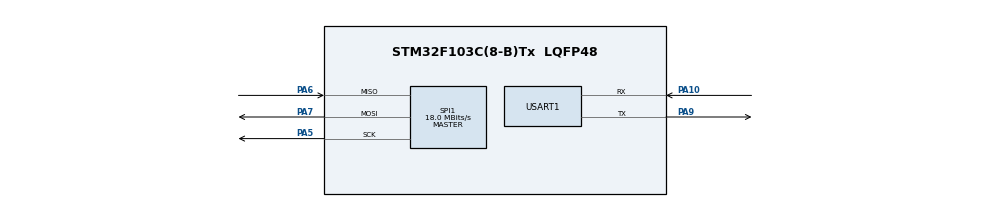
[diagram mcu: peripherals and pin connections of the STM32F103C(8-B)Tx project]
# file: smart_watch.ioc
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Mcu.Family=STM32F1
Mcu.Name=STM32F103C(8-B)Tx
Mcu.Package=LQFP48
NVIC.PriorityGroup=NVIC_PRIORITYGROUP_4
NVIC.SPI1_IRQn=true\:0\:0\:false\:false\:true\:true\:true\:true
NVIC.TIM3_IRQn=true\:15\:0\:false\:false\:true\:false\:true\:true
NVIC.TimeBase=TIM3_IRQn
NVIC.TimeBaseIP=TIM3
PA10.Mode=Asynchronous
PA10.Signal=USART1_RX
PA13.Mode=Serial_Wire
PA13.Signal=SYS_JTMS-SWDIO
PA14.Mode=Serial_Wire
PA14.Signal=SYS_JTCK-SWCLK
PA5.Mode=Full_Duplex_Master
PA5.Signal=SPI1_SCK
PA6.Mode=Full_Duplex_Master
PA6.Signal=SPI1_MISO
PA7.Mode=Full_Duplex_Master
PA7.Signal=SPI1_MOSI
PA9.Mode=Asynchronous
PA9.Signal=USART1_TX
PD0-OSC_IN.Mode=HSE-External-Oscillator
PD0-OSC_IN.Signal=RCC_OSC_IN
PD1-OSC_OUT.Mode=HSE-External-Oscillator
PD1-OSC_OUT.Signal=RCC_OSC_OUT
ProjectManager.HeapSize=0x200
ProjectManager.StackSize=0x400
ProjectManager.TargetToolchain=MDK-ARM V5.32
RCC.AHBCLKDivider=RCC_SYSCLK_DIV2
RCC.AHBFreq_Value=36000000
RCC.APB1CLKDivider=RCC_HCLK_DIV2
RCC.APB1Freq_Value=18000000
RCC.APB1TimFreq_Value=36000000
RCC.APB2Freq_Value=36000000
RCC.APB2TimFreq_Value=36000000
RCC.HCLKFreq_Value=36000000
RCC.PLLMUL=RCC_PLL_MUL9
RCC.PLLSourceVirtual=RCC_PLLSOURCE_HSE
RCC.SYSCLKFreq_VALUE=72000000
RCC.SYSCLKSource=RCC_SYSCLKSOURCE_PLLCLK
RCC.USBFreq_Value=72000000
SPI1.BaudRatePrescaler=SPI_BAUDRATEPRESCALER_2
SPI1.CalculateBaudRate=18.0 MBits/s
SPI1.Direction=SPI_DIRECTION_2LINES
SPI1.Mode=SPI_MODE_MASTER
SPI1.VirtualType=VM_MASTER
USART1.VirtualMode=VM_ASYNC
VP_SYS_VS_tim3.Mode=TIM3
VP_TIM4_VS_ClockSourceINT.Mode=Internal
board=custom

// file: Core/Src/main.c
/* USER CODE BEGIN Header */
/**
  ******************************************************************************
  * @file           : main.c
  * @brief          : Main program body
  ******************************************************************************
  * @attention
  *
  * Copyright (c) 2025 STMicroelectronics.
  * All rights reserved.
  *
  * This software is licensed under terms that can be found in the LICENSE file
  * in the root directory of this software component.
  * If no LICENSE file comes with this software, it is provided AS-IS.
  *
  ******************************************************************************
  */
/* USER CODE END Header */
#include "main.h"

/* USER CODE BEGIN Includes */
/* ---- Middleware Layer ---- */
#include "FreeRTOSConfig.h"
#include "FreeRTOS.h"
#include "task.h"

/* ---- Driver Layer ---- */
#include "AT45DB161D.h"

/* USER CODE END Includes */

void SystemClock_Config(void);
static void MX_GPIO_Init(void);
static void MX_SPI1_Init(void);
static void MX_USART1_UART_Init(void);
static void MX_TIM4_Init(void);

/* USER CODE BEGIN 0 */

/* Task in freeRTOS */
void TaskLED(void *param);

/* USER CODE END 0 */

int main(void)
{

  /* MCU Configuration--------------------------------------------------------*/

  /* Reset of all peripherals, Initializes the Flash interface and the Systick. */
  HAL_Init();

  /* Configure the system clock */
  SystemClock_Config();

  /* Initialize all configured peripherals */
  MX_GPIO_Init();
  MX_SPI1_Init();
  MX_USART1_UART_Init();
  MX_TIM4_Init();
  /* USER CODE BEGIN 2 */
	xTaskCreate(TaskLED, "LED", 128, NULL, 2, NULL);
	vTaskStartScheduler();
  /* USER CODE END 2 */

  /* Infinite loop */
  while (1)
  {

  }
}

void SystemClock_Config(void)
{
  LL_FLASH_SetLatency(LL_FLASH_LATENCY_2);
  while(LL_FLASH_GetLatency()!= LL_FLASH_LATENCY_2)
  {
  }
  LL_RCC_HSE_Enable();

   /* Wait till HSE is ready */
  while(LL_RCC_HSE_IsReady() != 1)
  {

  }
  LL_RCC_PLL_ConfigDomain_SYS(LL_RCC_PLLSOURCE_HSE_DIV_1, LL_RCC_PLL_MUL_9);
  LL_RCC_PLL_Enable();

   /* Wait till PLL is ready */
  while(LL_RCC_PLL_IsReady() != 1)
  {

  }
  LL_RCC_SetAHBPrescaler(LL_RCC_SYSCLK_DIV_2);
  LL_RCC_SetAPB1Prescaler(LL_RCC_APB1_DIV_2);
  LL_RCC_SetAPB2Prescaler(LL_RCC_APB2_DIV_1);
  LL_RCC_SetSysClkSource(LL_RCC_SYS_CLKSOURCE_PLL);

   /* Wait till System clock is ready */
  while(LL_RCC_GetSysClkSource() != LL_RCC_SYS_CLKSOURCE_STATUS_PLL)
  {

  }
  LL_SetSystemCoreClock(36000000);

   /* Update the time base */
  if (HAL_InitTick (TICK_INT_PRIORITY) != HAL_OK)
  {
    Error_Handler();
  }
}

static void MX_SPI1_Init(void)
{

  LL_SPI_InitTypeDef SPI_InitStruct = {0};

  LL_GPIO_InitTypeDef GPIO_InitStruct = {0};

  /* Peripheral clock enable */
  LL_APB2_GRP1_EnableClock(LL_APB2_GRP1_PERIPH_SPI1);

  LL_APB2_GRP1_EnableClock(LL_APB2_GRP1_PERIPH_GPIOA);
  /**SPI1 GPIO Configuration
  PA5   ------> SPI1_SCK
  PA6   ------> SPI1_MISO
  PA7   ------> SPI1_MOSI
  */
  GPIO_InitStruct.Pin = LL_GPIO_PIN_5|LL_GPIO_PIN_7;
  GPIO_InitStruct.Mode = LL_GPIO_MODE_ALTERNATE;
  GPIO_InitStruct.Speed = LL_GPIO_SPEED_FREQ_HIGH;
  GPIO_InitStruct.OutputType = LL_GPIO_OUTPUT_PUSHPULL;
  LL_GPIO_Init(GPIOA, &GPIO_InitStruct);

  GPIO_InitStruct.Pin = LL_GPIO_PIN_6;
  GPIO_InitStruct.Mode = LL_GPIO_MODE_FLOATING;
  LL_GPIO_Init(GPIOA, &GPIO_InitStruct);

  /* SPI1 interrupt Init */
  NVIC_SetPriority(SPI1_IRQn, NVIC_EncodePriority(NVIC_GetPriorityGrouping(),0, 0));
  NVIC_EnableIRQ(SPI1_IRQn);

  /* SPI1 parameter configuration*/
  SPI_InitStruct.TransferDirection = LL_SPI_FULL_DUPLEX;
  SPI_InitStruct.Mode = LL_SPI_MODE_MASTER;
  SPI_InitStruct.DataWidth = LL_SPI_DATAWIDTH_8BIT;
  SPI_InitStruct.ClockPolarity = LL_SPI_POLARITY_LOW;
  SPI_InitStruct.ClockPhase = LL_SPI_PHASE_1EDGE;
  SPI_InitStruct.NSS = LL_SPI_NSS_SOFT;
  SPI_InitStruct.BaudRate = LL_SPI_BAUDRATEPRESCALER_DIV2;
  SPI_InitStruct.BitOrder = LL_SPI_MSB_FIRST;
  SPI_InitStruct.CRCCalculation = LL_SPI_CRCCALCULATION_DISABLE;
  SPI_InitStruct.CRCPoly = 10;
  LL_SPI_Init(SPI1, &SPI_InitStruct);

}

static void MX_TIM4_Init(void)
{

  LL_TIM_InitTypeDef TIM_InitStruct = {0};

  /* Peripheral clock enable */
  LL_APB1_GRP1_EnableClock(LL_APB1_GRP1_PERIPH_TIM4);

  TIM_InitStruct.Prescaler = 0;
  TIM_InitStruct.CounterMode = LL_TIM_COUNTERMODE_UP;
  TIM_InitStruct.Autoreload = 65535;
  TIM_InitStruct.ClockDivision = LL_TIM_CLOCKDIVISION_DIV1;
  LL_TIM_Init(TIM4, &TIM_InitStruct);
  LL_TIM_DisableARRPreload(TIM4);
  LL_TIM_SetClockSource(TIM4, LL_TIM_CLOCKSOURCE_INTERNAL);
  LL_TIM_SetTriggerOutput(TIM4, LL_TIM_TRGO_RESET);
  LL_TIM_DisableMasterSlaveMode(TIM4);

}

static void MX_USART1_UART_Init(void)
{

  LL_USART_InitTypeDef USART_InitStruct = {0};

  LL_GPIO_InitTypeDef GPIO_InitStruct = {0};

  /* Peripheral clock enable */
  LL_APB2_GRP1_EnableClock(LL_APB2_GRP1_PERIPH_USART1);

  LL_APB2_GRP1_EnableClock(LL_APB2_GRP1_PERIPH_GPIOA);
  /**USART1 GPIO Configuration
  PA9   ------> USART1_TX
  PA10   ------> USART1_RX
  */
  GPIO_InitStruct.Pin = LL_GPIO_PIN_9;
  GPIO_InitStruct.Mode = LL_GPIO_MODE_ALTERNATE;
  GPIO_InitStruct.Speed = LL_GPIO_SPEED_FREQ_HIGH;
  GPIO_InitStruct.OutputType = LL_GPIO_OUTPUT_PUSHPULL;
  LL_GPIO_Init(GPIOA, &GPIO_InitStruct);

  GPIO_InitStruct.Pin = LL_GPIO_PIN_10;
  GPIO_InitStruct.Mode = LL_GPIO_MODE_FLOATING;
  LL_GPIO_Init(GPIOA, &GPIO_InitStruct);

  USART_InitStruct.BaudRate = 115200;
  USART_InitStruct.DataWidth = LL_USART_DATAWIDTH_8B;
  USART_InitStruct.StopBits = LL_USART_STOPBITS_1;
  USART_InitStruct.Parity = LL_USART_PARITY_NONE;
  USART_InitStruct.TransferDirection = LL_USART_DIRECTION_TX_RX;
  USART_InitStruct.HardwareFlowControl = LL_USART_HWCONTROL_NONE;
  USART_InitStruct.OverSampling = LL_USART_OVERSAMPLING_16;
  LL_USART_Init(USART1, &USART_InitStruct);
  LL_USART_ConfigAsyncMode(USART1);
  LL_USART_Enable(USART1);

}

static void MX_GPIO_Init(void)
{

  /* GPIO Ports Clock Enable */
  LL_APB2_GRP1_EnableClock(LL_APB2_GRP1_PERIPH_GPIOD);
  LL_APB2_GRP1_EnableClock(LL_APB2_GRP1_PERIPH_GPIOA);

}

/* USER CODE BEGIN 4 */
void TaskLED(void *param)
{
    while(1)
    {
        GPIOC->ODR ^= (1 << 13);   // Toggle LED PC13
        vTaskDelay(pdMS_TO_TICKS(500));
    }
}
/* USER CODE END 4 */

void HAL_TIM_PeriodElapsedCallback(TIM_HandleTypeDef *htim)
{
  if (htim->Instance == TIM3)
  {
    HAL_IncTick();
  }
}

void Error_Handler(void)
{
  __disable_irq();
  while (1)
  {
  }
}
